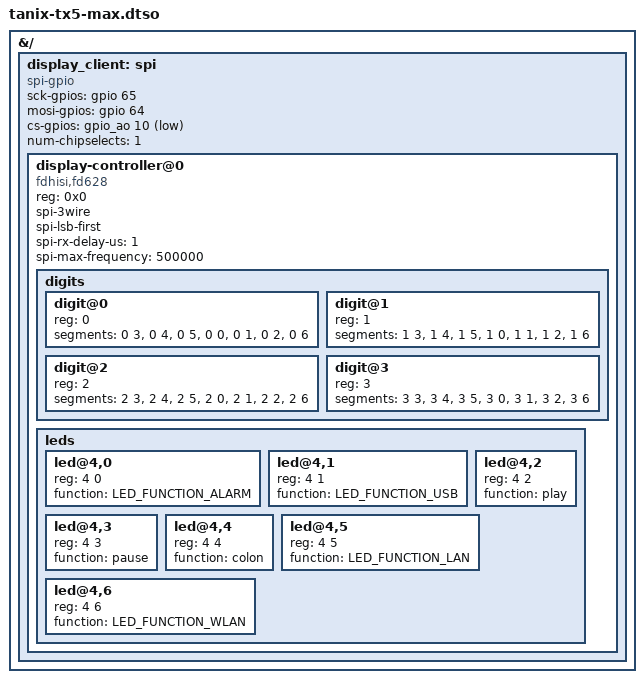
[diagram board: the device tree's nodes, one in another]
/dts-v1/;
/plugin/;

#include <dt-bindings/gpio/gpio.h>
#include <dt-bindings/leds/common.h>

&{/} {

	display_client: spi {
		#address-cells = <1>;
		#size-cells = <0>;
		compatible = "spi-gpio";
		sck-gpios = <&gpio 65 GPIO_ACTIVE_HIGH>;
		mosi-gpios = <&gpio 64 GPIO_ACTIVE_HIGH>;
		cs-gpios = <&gpio_ao 10 GPIO_ACTIVE_LOW>;
		num-chipselects = <1>;

		display-controller@0 {
			compatible = "fdhisi,fd628";
			reg = <0x0>;
			spi-3wire;
			spi-lsb-first;
			spi-rx-delay-us = <1>;
			spi-max-frequency = <500000>;

			digits {
				#address-cells = <1>;
				#size-cells = <0>;
				digit@0 {
					reg = <0>;
					segments = <0 3>,
						   <0 4>,
						   <0 5>,
						   <0 0>,
						   <0 1>,
						   <0 2>,
						   <0 6>;
				};
				digit@1 {
					reg = <1>;
					segments = <1 3>,
						   <1 4>,
						   <1 5>,
						   <1 0>,
						   <1 1>,
						   <1 2>,
						   <1 6>;
				};
				digit@2 {
					reg = <2>;
					segments = <2 3>,
						   <2 4>,
						   <2 5>,
						   <2 0>,
						   <2 1>,
						   <2 2>,
						   <2 6>;
				};
				digit@3 {
					reg = <3>;
					segments = <3 3>,
						   <3 4>,
						   <3 5>,
						   <3 0>,
						   <3 1>,
						   <3 2>,
						   <3 6>;
				};
			};

			leds {
				#address-cells = <2>;
				#size-cells = <0>;
				led@4,0 {
					reg = <4 0>;
					function = LED_FUNCTION_ALARM;
				};
				led@4,1 {
					reg = <4 1>;
					function = LED_FUNCTION_USB;
				};
				led@4,2 {
					reg = <4 2>;
					function = "play";
				};
				led@4,3 {
					reg = <4 3>;
					function = "pause";
				};
				led@4,4 {
					reg = <4 4>;
					function = "colon";
				};
				led@4,5 {
					reg = <4 5>;
					function = LED_FUNCTION_LAN;
				};
				led@4,6 {
					reg = <4 6>;
					function = LED_FUNCTION_WLAN;
				};
			}

		};
	};
};

